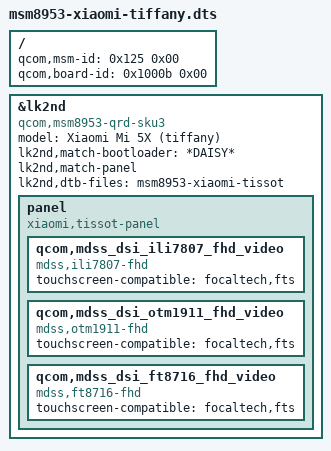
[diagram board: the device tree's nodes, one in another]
/dts-v1/;

#include <skeleton64.dtsi>
#include <lk2nd.dtsi>

/ {
	qcom,msm-id = <0x125 0x00>;
	qcom,board-id = <0x1000b 0x00>;
};

&lk2nd {
	model = "Xiaomi Mi 5X (tiffany)";
	compatible = "qcom,msm8953-qrd-sku3\0qcom,msm8953-qrd\0qcom,msm8953\0qcom,qrd";
	lk2nd,match-bootloader = "*DAISY*";
	lk2nd,match-panel;

	lk2nd,dtb-files = "msm8953-xiaomi-tissot";

	panel {
		compatible = "xiaomi,tissot-panel", "lk2nd,panel";

		qcom,mdss_dsi_ili7807_fhd_video {
			compatible = "mdss,ili7807-fhd";
			touchscreen-compatible = "focaltech,fts";
		};
		qcom,mdss_dsi_otm1911_fhd_video {
			compatible = "mdss,otm1911-fhd";
			touchscreen-compatible = "focaltech,fts";
		};
		qcom,mdss_dsi_ft8716_fhd_video {
			compatible = "mdss,ft8716-fhd";
			touchscreen-compatible = "focaltech,fts";
		};
	};
};
